# STM32MP153x register map
File version: 1.0
Registers are 32-bit, read-write, reset 0x0 unless marked. A register's access mark holds for its fields unless they carry their own. Offsets are from the block's base; [hi:lo] are bit positions; {n}, {i} and the like mark numbered series; 'fields as' and 'values as' point back to an identical list.

## HDP
Base 0x5002A000
0x00 HDP_CTRL — HDP Control
  [0] EN
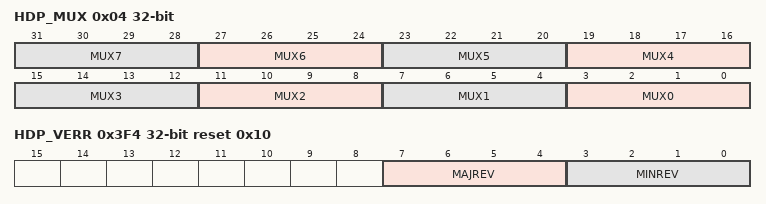
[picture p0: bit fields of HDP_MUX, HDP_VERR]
0x04 HDP_MUX — HDP multiplexing
  [4n+3:4n] MUX{n} (n=0..7)
0x10 HDP_VAL ro — HDP value
  [7:0] HDPVAL
0x14 HDP_GPOSET wo
  [7:0] HDPGPOSET
0x18 HDP_GPOCLR wo — HDP GPO clear
  [7:0] HDPGPOCLR
0x1C HDP_GPOVAL — HDP GPO value
  [7:0] HDPGPOVAL
0x3F4 HDP_VERR ro reset 0x10 — HDP version register
  [7:4] MAJREV, [3:0] MINREV
0x3F8 HDP_IPIDR ro reset 0x30002 — HDP IP identification register
  [31:0] ID
0x3FC HDP_SIDR ro reset 0xA3C5DD01 — HDP size identification register
  [31:0] SID

## SAI1 — SAI1 register block
Base 0x4400A000
Same registers: SAI2 0x4400B000, SAI3 0x4400C000, SAI4 0x50027000
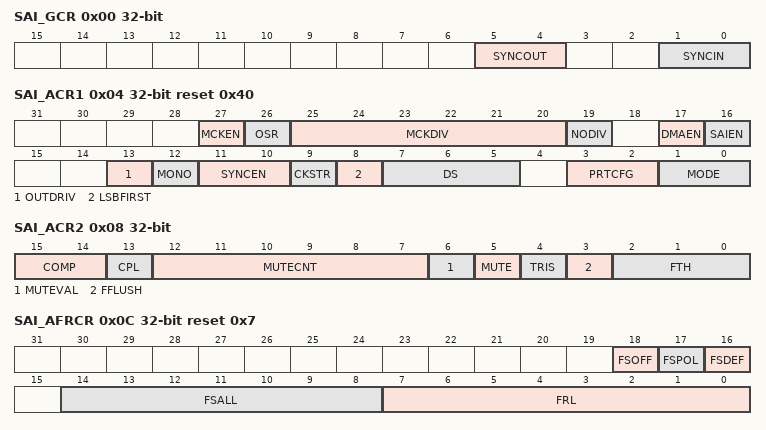
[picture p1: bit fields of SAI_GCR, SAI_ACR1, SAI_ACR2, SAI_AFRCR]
0x00 SAI_GCR — Global configuration register
  [5:4] SYNCOUT, [1:0] SYNCIN
0x04 SAI_ACR1 reset 0x40 — Configuration register 1
  [27] MCKEN, [26] OSR, [25:20] MCKDIV, [19] NODIV, [17] DMAEN, [16] SAIEN, [13] OUTDRIV, [12] MONO, [11:10] SYNCEN, [9] CKSTR, [8] LSBFIRST, [7:5] DS, [3:2] PRTCFG, [1:0] MODE
0x08 SAI_ACR2 access per field — Configuration register 2
  [15:14] COMP rw, [13] CPL rw, [12:7] MUTECNT rw, [6] MUTEVAL rw, [5] MUTE rw, [4] TRIS rw, [3] FFLUSH wo, [2:0] FTH rw
0x0C SAI_AFRCR access per field reset 0x7 — This register has no meaning in and SPDIF audio protocol
  [18] FSOFF rw, [17] FSPOL rw, [16] FSDEF ro, [14:8] FSALL rw, [7:0] FRL rw
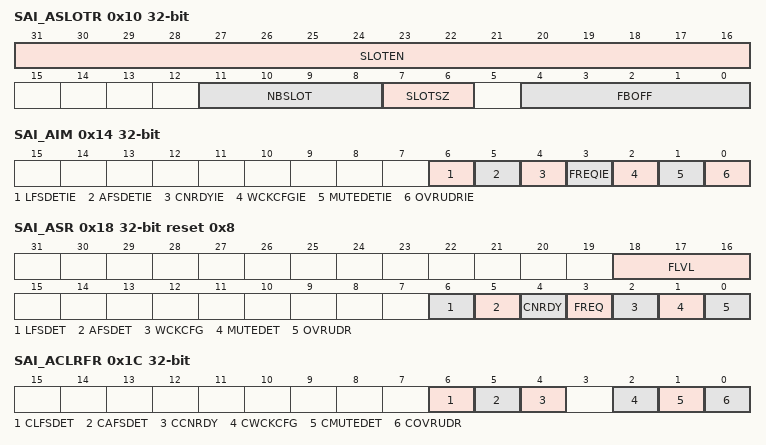
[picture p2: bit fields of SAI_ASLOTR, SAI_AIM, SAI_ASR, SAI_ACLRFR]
0x10 SAI_ASLOTR — This register has no meaning in and SPDIF audio protocol
  [31:16] SLOTEN, [11:8] NBSLOT, [7:6] SLOTSZ, [4:0] FBOFF
0x14 SAI_AIM — Interrupt mask register
  [6] LFSDETIE, [5] AFSDETIE, [4] CNRDYIE, [3] FREQIE, [2] WCKCFGIE, [1] MUTEDETIE, [0] OVRUDRIE
0x18 SAI_ASR ro reset 0x8 — Status register
  [18:16] FLVL, [6] LFSDET, [5] AFSDET, [4] CNRDY, [3] FREQ, [2] WCKCFG, [1] MUTEDET, [0] OVRUDR
0x1C SAI_ACLRFR wo — Clear flag register
  [6] CLFSDET, [5] CAFSDET, [4] CCNRDY, [2] CWCKCFG, [1] CMUTEDET, [0] COVRUDR
0x20 SAI_ADR — Data register
  [31:0] DATA
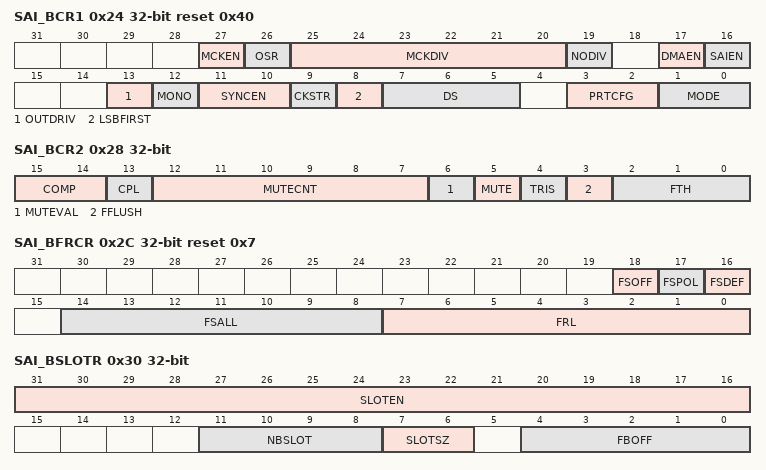
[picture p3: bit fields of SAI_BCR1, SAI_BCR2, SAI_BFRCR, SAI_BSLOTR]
0x24 SAI_BCR1 reset 0x40 — Configuration register 1
  fields as SAI_ACR1
0x28 SAI_BCR2 access per field — Configuration register 2
  fields as SAI_ACR2
0x2C SAI_BFRCR access per field reset 0x7 — This register has no meaning in and SPDIF audio protocol
  fields as SAI_AFRCR
0x30 SAI_BSLOTR — This register has no meaning in and SPDIF audio protocol
  [31:16] SLOTEN, [11:8] NBSLOT, [7:6] SLOTSZ, [4:0] FBOFF
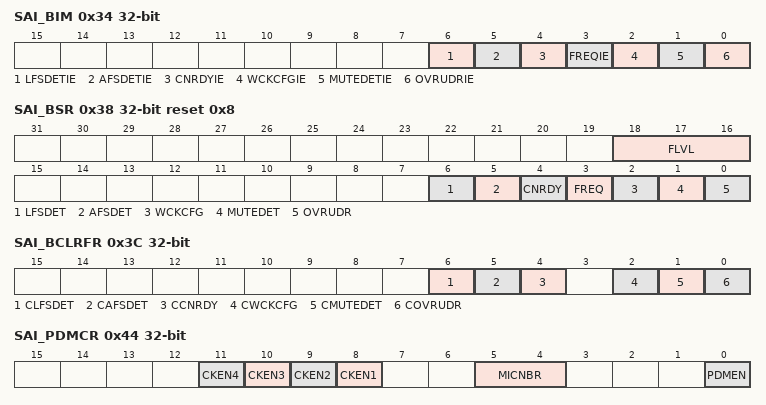
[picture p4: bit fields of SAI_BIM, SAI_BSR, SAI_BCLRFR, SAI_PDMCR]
0x34 SAI_BIM — Interrupt mask register
  fields as SAI_AIM
0x38 SAI_BSR ro reset 0x8 — Status register
  fields as SAI_ASR
0x3C SAI_BCLRFR wo — Clear flag register
  fields as SAI_ACLRFR
0x40 SAI_BDR — Data register
  [31:0] DATA
0x44 SAI_PDMCR — PDM control register
  [n+7] CKEN{n} (n=1..4), [5:4] MICNBR, [0] PDMEN
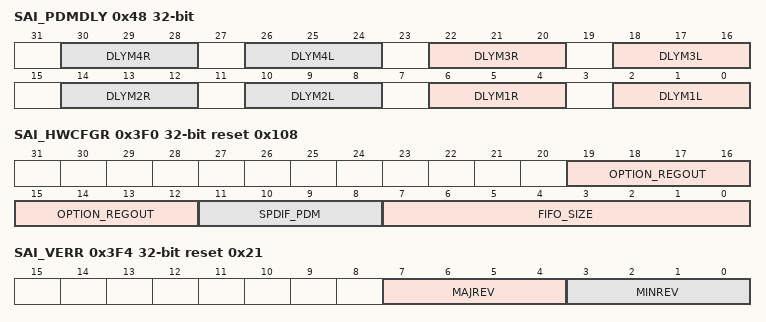
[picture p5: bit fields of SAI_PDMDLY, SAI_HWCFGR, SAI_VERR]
0x48 SAI_PDMDLY — PDM delay register
  [8n-2:8n-4] DLYM{n}R (n=1..4), [8n-6:8n-8] DLYM{n}L (n=1..4)
0x3F0 SAI_HWCFGR ro reset 0x108 — SAI hardware configuration register
  [19:12] OPTION_REGOUT, [11:8] SPDIF_PDM, [7:0] FIFO_SIZE
0x3F4 SAI_VERR ro reset 0x21 — SAI version register
  [7:4] MAJREV, [3:0] MINREV
0x3F8 SAI_IPIDR ro reset 0x130031 — SAI identification register
  [31:0] ID
0x3FC SAI_SIDR ro reset 0xA3C5DD01 — SAI size identification register
  [31:0] SID

## VREFBUF
Base 0x50025000
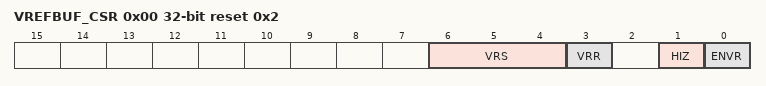
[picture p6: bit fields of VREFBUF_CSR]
0x00 VREFBUF_CSR access per field reset 0x2 — VREFBUF control and status register
  [6:4] VRS rw, [3] VRR ro, [1] HIZ rw, [0] ENVR rw
0x04 VREFBUF_CCR — VREFBUF calibration control register
  [5:0] TRIM

## LPTIM1
Base 0x40009000
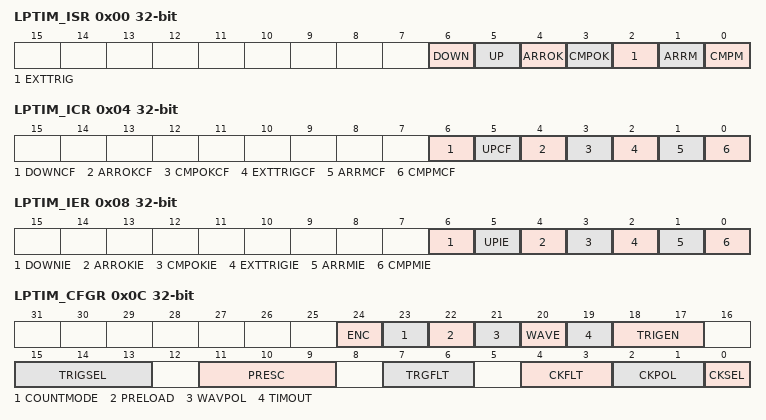
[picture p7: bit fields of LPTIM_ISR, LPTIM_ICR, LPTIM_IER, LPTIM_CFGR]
0x00 LPTIM_ISR ro — LPTIM interrupt and status register
  [6] DOWN, [5] UP, [4] ARROK, [3] CMPOK, [2] EXTTRIG, [1] ARRM, [0] CMPM
0x04 LPTIM_ICR wo — LPTIM interrupt clear register
  [6] DOWNCF, [5] UPCF, [4] ARROKCF, [3] CMPOKCF, [2] EXTTRIGCF, [1] ARRMCF, [0] CMPMCF
0x08 LPTIM_IER — LPTIM interrupt enable register
  [6] DOWNIE, [5] UPIE, [4] ARROKIE, [3] CMPOKIE, [2] EXTTRIGIE, [1] ARRMIE, [0] CMPMIE
0x0C LPTIM_CFGR — LPTIM configuration register
  [24] ENC, [23] COUNTMODE, [22] PRELOAD, [21] WAVPOL, [20] WAVE, [19] TIMOUT, [18:17] TRIGEN, [15:13] TRIGSEL, [11:9] PRESC, [7:6] TRGFLT, [4:3] CKFLT, [2:1] CKPOL, [0] CKSEL
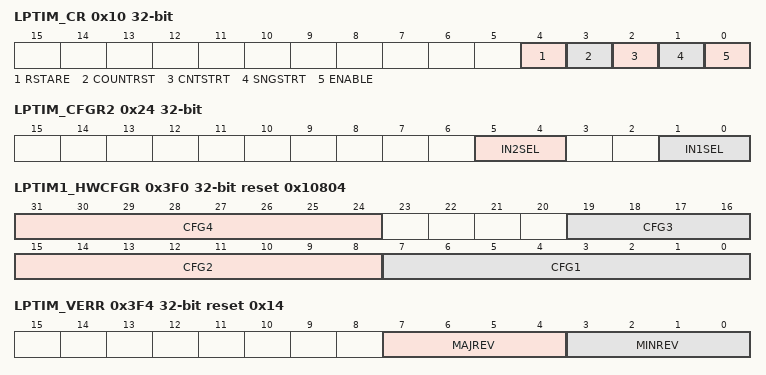
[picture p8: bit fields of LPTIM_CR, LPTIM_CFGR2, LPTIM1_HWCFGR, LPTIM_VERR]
0x10 LPTIM_CR — LPTIM control register
  [4] RSTARE, [3] COUNTRST, [2] CNTSTRT, [1] SNGSTRT, [0] ENABLE
0x14 LPTIM_CMP — LPTIM compare register
  [15:0] CMP
0x18 LPTIM_ARR reset 0x1 — LPTIM autoreload register
  [15:0] ARR
0x1C LPTIM_CNT ro — LPTIM counter register
  [15:0] CNT
0x24 LPTIM_CFGR2 — LPTIM configuration register 2
  [5:4] IN2SEL, [1:0] IN1SEL
0x3F0 LPTIM1_HWCFGR ro reset 0x10804 — LPTIM 1 peripheral hardware configuration register
  [31:24] CFG4, [19:16] CFG3, [15:8] CFG2, [7:0] CFG1
0x3F4 LPTIM_VERR ro reset 0x14 — LPTIM peripheral version identification register
  [7:4] MAJREV, [3:0] MINREV
0x3F8 LPTIM_PIDR ro reset 0x120011 — LPTIM peripheral type identification register
  [31:0] P_ID
0x3FC LPTIM_SIDR ro reset 0xA3C5DD01 — LPTIM registers map size identification register
  [31:0] S_ID

## LPTIM2
Base 0x50021000
Registers as LPTIM1 (with LPTIM1 read as LPTIM2); these are added or differ:
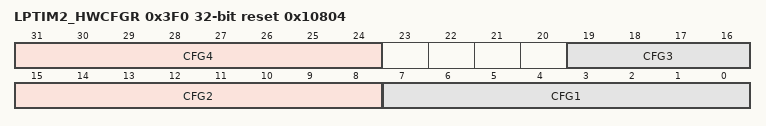
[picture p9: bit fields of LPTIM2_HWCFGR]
0x3F0 LPTIM2_HWCFGR ro reset 0x10804 — LPTIM 2 peripheral hardware configuration register
  [31:24] CFG4, [19:16] CFG3, [15:8] CFG2, [7:0] CFG1

## LPTIM4
Base 0x50023000
Registers as LPTIM1 (with LPTIM1 read as LPTIM4); these are added or differ:
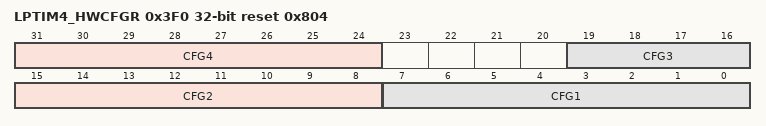
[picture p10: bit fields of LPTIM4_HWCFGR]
0x3F0 LPTIM4_HWCFGR ro reset 0x804 — LPTIM 4 peripheral hardware configuration register
  [31:24] CFG4, [19:16] CFG3, [15:8] CFG2, [7:0] CFG1

## LPTIM5
Base 0x50024000
Registers as LPTIM1 (with LPTIM1 read as LPTIM5); these are added or differ:
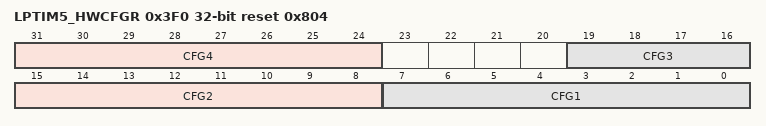
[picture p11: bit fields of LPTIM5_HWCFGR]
0x3F0 LPTIM5_HWCFGR ro reset 0x804 — LPTIM 5 peripheral hardware configuration register
  [31:24] CFG4, [19:16] CFG3, [15:8] CFG2, [7:0] CFG1

## LPTIM3
Base 0x50022000
Registers as LPTIM1 (with LPTIM1 read as LPTIM3), without LPTIM_CFGR2; these are added or differ:
0x24 LPTIM3_CFGR2 — LPTIM3 configuration register 2
  [1:0] IN1SEL
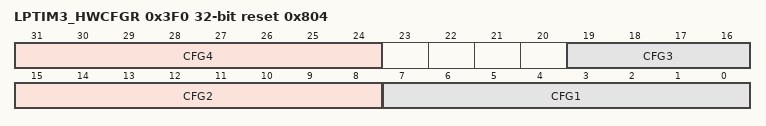
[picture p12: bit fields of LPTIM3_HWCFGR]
0x3F0 LPTIM3_HWCFGR ro reset 0x804 — LPTIM 3 peripheral hardware configuration register
  [31:24] CFG4, [19:16] CFG3, [15:8] CFG2, [7:0] CFG1
